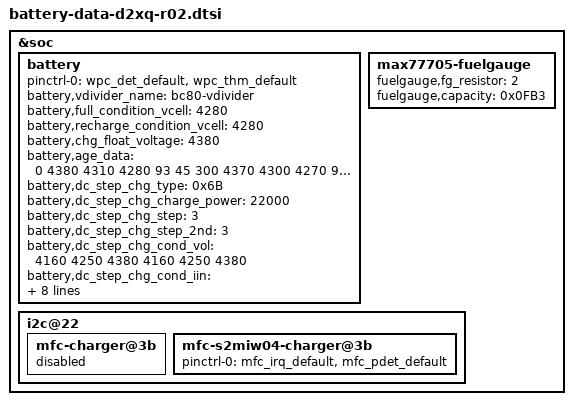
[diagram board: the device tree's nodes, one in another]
/* Copyright (c) 2014, The Linux Foundation. All rights reserved.
 *
 * This program is free software; you can redistribute it and/or modify
 * it under the terms of the GNU General Public License version 2 and
 * only version 2 as published by the Free Software Foundation.
 *
 * This program is distributed in the hope that it will be useful,
 * but WITHOUT ANY WARRANTY; without even the implied warranty of
 * MERCHANTABILITY or FITNESS FOR A PARTICULAR PURPOSE.  See the
 * GNU General Public License for more details.
 */

/* This dtsi is for hw rev from 02 to 03 */
#include "battery-data-d2xq-common.dtsi"
#include "battery-rx-data-d2q-lsi.dtsi"

&soc {
	battery {
		pinctrl-0 = <&wpc_det_default &wpc_thm_default>;
		battery,vdivider_name = "bc80-vdivider";
		battery,full_condition_vcell = <4280>;
		battery,recharge_condition_vcell = <4280>;
		battery,chg_float_voltage = <4380>;

		/* cycle, chg_float_voltage, recharge_condition_vcell, full_condition_vcell, full_condition_soc, step charging condition */
		battery,age_data = <0 4380 4310 4280 93 45
				300 4370 4300 4270 92 45
				400 4350 4280 4250 91 45
				700 4330 4260 4230 90 45
				1000 4280 4210 4180 89 45>;

		/* direct step charging option */
		battery,dc_step_chg_type = <0x6B>; /* origin(0x6B), soc option is temporary removed */
		battery,dc_step_chg_charge_power = <22000>;
		battery,dc_step_chg_step = <3>;
		battery,dc_step_chg_step_2nd = <3>;
		battery,dc_step_chg_cond_vol = <4160 4250 4380 4160 4250 4380>; /*<25w 3step, 45w 3step> STEP_CHARGING_CONDITION_VOLTAGE */ 
		battery,dc_step_chg_cond_iin = <1950 1550 0 1950 1550 0>; /* <25w 3step, 45w 3step> STEP_CHARGING_CONDITION_INPUT_CURRENT */
		battery,dc_step_chg_iin_check_cnt = <3>;
		battery,dc_step_chg_cond_soc = <40 60 100 40 60 100>; /* <25w 3step, 45w 3step> STEP_CHARGING_CONDITION_SOC */
		battery,dc_step_chg_val_vfloat = <4160 4250 4380 4160 4250 4380>; /* <25w 3step, 45w 3step> STEP_CHARGING_CONDITION_FLOAT_VOLTAGE */
		battery,dc_step_chg_val_iout = <5100 3900 3100 5100 3900 3100>; /* <25w 3step, 45w 3step> */
	};

	max77705-fuelgauge {
		fuelgauge,fg_resistor = <2>;
		fuelgauge,capacity = <0x0FB3>;
	};

	i2c@22 {
		mfc-charger@3b {
			status = "disabled";
		};		
		mfc-s2miw04-charger@3b {
			pinctrl-0 = <&mfc_irq_default &mfc_pdet_default>;	
			/delete-property/ battery,ping_nen;
			/delete-property/ battery,vrect_int;
		};
	};
};
